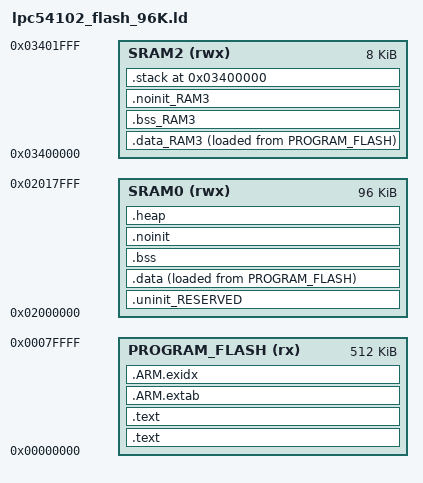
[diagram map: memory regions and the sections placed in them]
/*
 * GENERATED FILE - DO NOT EDIT
 * (c) Code Red Technologies Ltd, 2008-2013
 * (c) NXP Semiconductors 2013-2017
 * Generated linker script file for LPC54102J512
 * Created from linkscript.ldt by FMCreateLinkLibraries
 * Using Freemarker v2.3.23
 * MCUXpresso IDE Debug Build on Oct 16, 2017 4:42:58 PM
 */

GROUP (
  libgcc.a
  libc.a
  libg.a
  libm.a
  libnosys.a
)

MEMORY
{
  /* Define each memory region */
  PROGRAM_FLASH (rx) : ORIGIN = 0x0, LENGTH = 0x80000 /* 512K bytes (alias Flash) */  
  SRAM0 (rwx) : ORIGIN = 0x2000000, LENGTH = 0x18000 /* 96K bytes (alias RAM) */  
  SRAM2 (rwx) : ORIGIN = 0x3400000, LENGTH = 0x2000 /* 8K bytes (alias RAM3) */  
}

  /* Define a symbol for the top of each memory region */
  __base_PROGRAM_FLASH = 0x0  ; /* PROGRAM_FLASH */  
  __base_Flash = 0x0 ; /* Flash */  
  __top_PROGRAM_FLASH = 0x0 + 0x80000 ; /* 512K bytes */  
  __top_Flash = 0x0 + 0x80000 ; /* 512K bytes */  
  __base_SRAM0 = 0x2000000  ; /* SRAM0 */  
  __top_SRAM0 = 0x2000000 + 0x18000 ; /* 96K bytes */  
  __base_SRAM2 = 0x3400000  ; /* SRAM2 */  
  __top_SRAM2 = 0x3400000 + 0x2000 ; /* 8K bytes */  

ENTRY(ResetISR)

SECTIONS
{
    /* MAIN TEXT SECTION */
    .text : ALIGN(4)
    {
        FILL(0xff)
        __vectors_start__ = ABSOLUTE(.) ;
        KEEP(*(.isr_vector))
        /* Global Section Table */
        . = ALIGN(4) ;
        __section_table_start = .;
        __data_section_table = .;
        LONG(LOADADDR(.data));
        LONG(    ADDR(.data));
        LONG(  SIZEOF(.data));
        LONG(LOADADDR(.data_RAM3));
        LONG(    ADDR(.data_RAM3));
        LONG(  SIZEOF(.data_RAM3));
        __data_section_table_end = .;
        __bss_section_table = .;
        LONG(    ADDR(.bss));
        LONG(  SIZEOF(.bss));
        LONG(    ADDR(.bss_RAM3));
        LONG(  SIZEOF(.bss_RAM3));
        __bss_section_table_end = .;
        __section_table_end = . ;
	    /* End of Global Section Table */

        *(.after_vectors*)



    } >PROGRAM_FLASH

    .text : ALIGN(4)
    {
        *(.text*)
        *(.rodata .rodata.* .constdata .constdata.*)
        . = ALIGN(4);
    } > PROGRAM_FLASH
    /*
     * for exception handling/unwind - some Newlib functions (in common
     * with C++ and STDC++) use this. 
     */
    .ARM.extab : ALIGN(4) 
    {
        *(.ARM.extab* .gnu.linkonce.armextab.*)
    } > PROGRAM_FLASH
    __exidx_start = .;

    .ARM.exidx : ALIGN(4)
    {
        *(.ARM.exidx* .gnu.linkonce.armexidx.*)
    } > PROGRAM_FLASH
    __exidx_end = .;

    _etext = .;

    /* DATA section for SRAM2 */
    .data_RAM3 : ALIGN(4)
    {
        FILL(0xff)
        PROVIDE(__start_data_RAM3 = .) ;
        *(.ramfunc.$RAM3)
        *(.ramfunc.$SRAM2)
        *(.data.$RAM3*)
        *(.data.$SRAM2*)
        . = ALIGN(4) ;
        PROVIDE(__end_data_RAM3 = .) ;
     } > SRAM2 AT>PROGRAM_FLASH

    /* MAIN DATA SECTION */
    .uninit_RESERVED : ALIGN(4)
    {
        KEEP(*(.bss.$RESERVED*))
        . = ALIGN(4) ;
        _end_uninit_RESERVED = .;
    } > SRAM0
    /* Main DATA section (SRAM0) */
    .data : ALIGN(4)
    {
       FILL(0xff)
       _data = . ;
       *(vtable)
       *(.ramfunc*)
       *(.data*)
       . = ALIGN(4) ;
       _edata = . ;
    } > SRAM0 AT>PROGRAM_FLASH
    /* BSS section for SRAM2 */
    .bss_RAM3 : ALIGN(4)
    {
       PROVIDE(__start_bss_RAM3 = .) ;
       *(.bss.$RAM3*)
       *(.bss.$SRAM2*)
       . = ALIGN (. != 0 ? 4 : 1) ; /* avoid empty segment */
       PROVIDE(__end_bss_RAM3 = .) ;
    } > SRAM2 
    /* MAIN BSS SECTION */
    .bss : ALIGN(4)
    {
        _bss = .;
        *(.bss*)
        *(COMMON)
        . = ALIGN(4) ;
        _ebss = .;
        PROVIDE(end = .);
    } > SRAM0
    /* NOINIT section for SRAM2 */
    .noinit_RAM3 (NOLOAD) : ALIGN(4)
    {
       *(.noinit.$RAM3*)
       *(.noinit.$SRAM2*)
       . = ALIGN(4) ;
    } > SRAM2 
    /* DEFAULT NOINIT SECTION */
    .noinit (NOLOAD): ALIGN(4)
    {
        _noinit = .;
        *(.noinit*) 
         . = ALIGN(4) ;
        _end_noinit = .;
    } > SRAM0
    .heap :  ALIGN(4)
    {
        PROVIDE(_pvHeapStart = .);
        . += 0xE800;
		. = ALIGN(4);
        PROVIDE(_pvHeapLimit = .);
    } > SRAM0
    /*
	.heap2stackfill  : 
    {
        . += 0x1000;
    } > SRAM2
	*/
    .stack ORIGIN(SRAM2) :  ALIGN(4)
    {
        _vStackBase = .;
        . = ALIGN(4);
	. += 0x800;
        _vStackTop = .;
	_vHeap2Base = .;
	. += 0x1800;
    } > SRAM2

    /* ## Create checksum value (used in startup) ## */

    PROVIDE(__valid_user_code_checksum = 0 - 
                                         (_vStackTop 
                                         + (ResetISR + 1) 
                                         + (( DEFINED(NMI_Handler) ? NMI_Handler : M0_NMI_Handler ) + 1) 
                                         + (( DEFINED(HardFault_Handler) ? HardFault_Handler : M0_HardFault_Handler ) + 1) 
                                         )
           );
}
